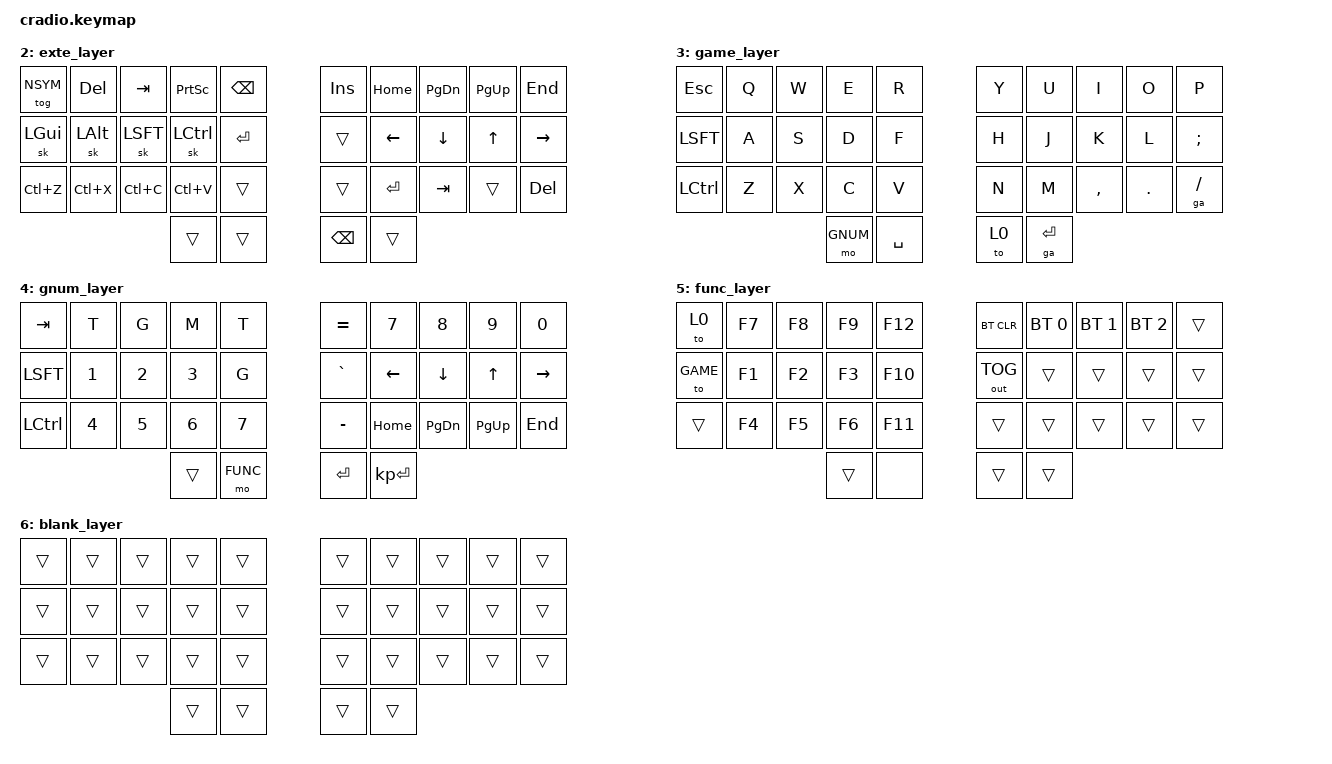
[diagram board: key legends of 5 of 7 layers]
// silicic-zmk cradio (sweep) keymap.
// (c) 2024 `silikeite`.
// SPDX-License-Identifier: MIT

#include <behaviors.dtsi>
#include <dt-bindings/zmk/keys.h>
#include <dt-bindings/zmk/bt.h>
#include <dt-bindings/zmk/outputs.h>

// Layers
#define MAIN 0
#define NSYM 1
#define EXTE 2

#define GAME 3
#define GNUM 4

#define FUNC 5

#define HRML(k1, k2, k3, k4) &ht LGUI k1 &ht LALT k2 &ht LSHFT k3 &ht LCTRL k4
#define HRMR(k1, k2, k3, k4) &ht RCTRL k1 &ht RSHFT k2 &ht RALT k3 &ht RGUI k4

/ {
    behaviors {
        // urob's timeless hold taps
        ht: home_tap {
            compatible = "zmk,behavior-hold-tap";
            #binding-cells = <2>;
            flavor = "balanced";
            tapping-term-ms = <280>;
            quick-tap-ms = <175>;
            require-prior-idle-ms = <150>;
            bindings = <&sk>, <&kp>;
            hold-trigger-on-release;
        };
        tt: thumb_tap {
            compatible = "zmk,behavior-hold-tap";
            #binding-cells = <2>;
            flavor = "hold-preferred";
            tapping-term-ms = <280>;
            quick-tap-ms = <175>;
            require-prior-idle-ms = <150>;
            bindings = <&mo>, <&kp>;
            hold-trigger-on-release;
        };
        ts: thumb_stick {
            compatible = "zmk,behavior-hold-tap";
            #binding-cells = <2>;
            flavor = "balanced";
            tapping-term-ms = <280>;
            quick-tap-ms = <175>;
            require-prior-idle-ms = <150>;
            bindings = <&sl>, <&kpmmCW>;
            hold-trigger-on-release;
        };

        // Mod morph sets.
        kpmmD: mod_morph_d {
            compatible = "zmk,behavior-mod-morph";
            #binding-cells = <0>;
            bindings = <&kp D>, <&kp V>;
            mods = <(MOD_LCTL|MOD_RCTL)>;
            keep-mods = <(MOD_LCTL|MOD_RCTL)>;
        };
        kpmmV: mod_morph_v {
            compatible = "zmk,behavior-mod-morph";
            #binding-cells = <0>;
            bindings = <&kp V>, <&kp D>;
            mods = <(MOD_LCTL|MOD_RCTL)>;
            keep-mods = <(MOD_LCTL|MOD_RCTL)>;
        };
        kpmmCO: mod_morph_comma {
            compatible = "zmk,behavior-mod-morph";
            #binding-cells = <0>;
            bindings = <&kp COMMA>, <&kp LPAR>;
            mods = <(MOD_LSFT|MOD_RSFT)>;
        };
        kpmmDO: mod_morph_dot {
            compatible = "zmk,behavior-mod-morph";
            #binding-cells = <0>;
            bindings = <&kp DOT>, <&kp RPAR>;
            mods = <(MOD_LSFT|MOD_RSFT)>;
        };
        kpmmN1: mod_morph_one {
            compatible = "zmk,behavior-mod-morph";
            #binding-cells = <0>;
            bindings = <&kp N1>, <&kp TILDE>;
            mods = <(MOD_LSFT|MOD_RSFT)>;
        };
        kpmmCW: mod_morph_capsword {
            compatible = "zmk,behavior-mod-morph";
            #binding-cells = <0>;
            bindings = <&sk LSFT>, <&caps_word>;
            mods = <(MOD_LSFT|MOD_RSFT)>;
        };
    };

    combos {
        compatible = "zmk,combos";
        
        // Normal mode cob

        combo_star {
            timeout-ms = <20>;
            layers = <0>;
            key-positions = <6 7>;
            require-prior-idle-ms = <150>;
            bindings = <&kp STAR>;
        };
        combo_minus {
            timeout-ms = <20>;
            layers = <0>;
            key-positions = <16 17>;
            require-prior-idle-ms = <150>;
            bindings = <&kp MINUS>;
        };
        combo_under {
            timeout-ms = <20>;
            layers = <0>;
            key-positions = <17 18>;
            require-prior-idle-ms = <150>;
            bindings = <&kp UNDER>;
        };
        combo_bspc {
            timeout-ms = <20>;
            layers = <0>;
            key-positions = <18 19>;
            require-prior-idle-ms = <150>;
            bindings = <&kp BSPC>;
        };
        combo_colon {
            timeout-ms = <20>;
            layers = <0>;
            key-positions = <26 27>;
            require-prior-idle-ms = <150>;
            bindings = <&kp COLON>;
        };
        combo_semi {
            timeout-ms = <20>;
            layers = <0>;
            key-positions = <27 28>;
            require-prior-idle-ms = <150>;
            bindings = <&kp SEMI>;
        };
        combo_excl {
            timeout-ms = <20>;
            layers = <0>;
            key-positions = <28 29>;
            require-prior-idle-ms = <150>;
            bindings = <&kp EXCL>;
        };

        // Resets
        combo_reset_left {
            timeout-ms = <20>;
            layers = <FUNC>;
            key-positions = <21 22 23>;
            require-prior-idle-ms = <150>;
            bindings = <&bootloader>;
        };
        combo_reset_right {
            timeout-ms = <20>;
            layers = <FUNC>;
            key-positions = <26 27 28>;
            require-prior-idle-ms = <150>;
            bindings = <&bootloader>;
        };

        // Switch to NumLk mode
        combo_mins_left {
            timeout-ms = <20>;
            layers = <NSYM>;
            key-positions = <12 13>;
            require-prior-idle-ms = <150>;
            bindings = <&kp MINUS>;
        };

        combo_esc {
            timeout-ms = <20>;
            layers = <0>;
            key-positions = <30 31>;
            require-prior-idle-ms = <100>;
            bindings = <&kp ESC>;
        };
    };

    macros {
        ga: game_alpha {
            compatible = "zmk,behavior-macro-one-param";
            #binding-cells = <1>;
            bindings
                = <&to 0>
                , <&macro_param_1to1>
                , <&kp MACRO_PLACEHOLDER>
            ;
        };
    };

    keymap {
        compatible = "zmk,keymap";

        // Standard, two-handed layers.

        default_layer {
            bindings = <
        //╭──────────┬──────────┬──────────┬──────────┬──────────╮   ╭──────────┬──────────┬──────────┬──────────┬──────────╮
        //│  Q       │  W       │  F       │  P       │  B       │   │  J       │  L       │  U       │  Y       │  ' "     │
            &kp Q      &kp W      &kp F      &kp P      &kp B          &kp J      &kp L      &kp U      &kp Y      &kp SQT
        //├──────────┼──────────┼──────────┼──────────┼──────────┤   ├──────────┼──────────┼──────────┼──────────┼──────────┤
        //│  A       │  R       │  S       │  T       │  G       │   │  M       │  N      (-) E      (_)  I      │  O       │
            HRML(A,     R,         S,         T)        &kp G          &kp M      HRMR(N,     E,          I,        O)
        //├──────────┼──────────┼──────────┼──────────┼──────────┤   ├──────────┼──────────┼──────────┼──────────┼──────────┤
        //│  Z       │  X       │  C       │  D       │  V       │   │  K       │  H      (:) , (    (;) . )    (!) / ?     │
            &kp Z      &kp X      &kp C      &kpmmD     &kpmmV         &kp K      &kp H      &kpmmCO   &kpmmDO     &kp FSLH
        //╰──────────┴──────────┴──────────┼──────────┼──────────┤   ├──────────┼──────────┼──────────┴──────────┴──────────╯
        //                                 |  Tab/Ex  |  _/Ex    |   | ⬆️/1#    |  ↩️/Fn   |
                                         &tt FUNC TAB &tt EXTE SPACE &ts NSYM 0 &tt FUNC RET
        //                                 ╰──────────┴──────────╯   ╰──────────┴──────────╯
            >;
        };

        nsym_layer {
            bindings = <
        //╭──────────┬──────────┬──────────┬──────────┬──────────╮   ╭──────────┬──────────┬──────────┬──────────┬──────────╮
        //│  ~       │  7 &     │  8 *     │  9 (     │          │   │          │  🌍      │  [       │  ]       │  ` ~     │
            &kp TILDE  &kp N7     &kp N8     &kp N9     &trans         &trans     &kp LANG1  &kp LBKT   &kp RBKT   &kp GRAVE   
        //├──────────┼──────────┼──────────┼──────────┼──────────┤   ├──────────┼──────────┼──────────┼──────────┼──────────┤
        //│  . >     │  1 !     │  2 @     │  3 #     │  = +     │   │          │  📋      │  {       │  }       │  ; :     │
            HRML(DOT,  N1,        N2,        N3)        &kp EQUAL      &trans     HRMR(K_APP, LBRC,     RBRC,      SEMI)  
        //├──────────┼──────────┼──────────┼──────────┼──────────┤   ├──────────┼──────────┼──────────┼──────────┼──────────┤
        //│  , <     │  4 $     │  5 %     │  6 ^     │          │   │          │ = +      │  <       │  >       │  \ |     │
            &kp COMMA  &kp N4     &kp N5     &kp N6     &trans         &trans     &kp EQUAL  &kp LT     &kp GT     &kp BSLH   
        //╰──────────┴──────────┴──────────┼──────────┼──────────┤   ├──────────┼──────────┼──────────┴──────────┴──────────╯
        //                                 |          |  0/Ex    |   | XXXXXXXX |          |
                                             &trans    &tt EXTE N0     &trans     &trans
        //                                 ╰──────────┴──────────╯   ╰──────────┴──────────╯
            >;
        };

        exte_layer {
            bindings = <
        //╭──────────┬──────────┬──────────┬──────────┬──────────╮   ╭──────────┬──────────┬──────────┬──────────┬──────────╮
        //│  NumLk   │  DEL     │  TAB     │  PRINT   │  BSPC    │   │  INS     │  HOME    │  PGDN    │  PGUP    │  END     │
            &tog NSYM  &kp DEL    &kp TAB    &kp PSCRN  &kp BSPC       &kp INS    &kp HOME  &kp PG_DN  &kp PG_UP   &kp END 
        //├──────────┼──────────┼──────────┼──────────┼──────────┤   ├──────────┼──────────┼──────────┼──────────┼──────────┤
        //│  META    │  ALT     │  SHIFT   │  CTRL    │  ↩️      │   │          │  LEFT    │  DOWN    │  UP      │  RIGHT   |
            &sk LGUI   &sk LALT   &sk LSFT   &sk LCTL   &kp RET        &trans     &kp LEFT   &kp DOWN   &kp UP     &kp RIGHT      
        //├──────────┼──────────┼──────────┼──────────┼──────────┤   ├──────────┼──────────┼──────────┼──────────┼──────────┤
        //│  UNDO    │  CUT     │  COPY    │  PASTE   │          │   │          │  RET     │  TAB     │          │   DEL    │
            &kp LC(Z)  &kp LC(X)  &kp LC(C)  &kp LC(V)  &trans         &trans     &kp RET    &kp TAB     &trans     &kp DEL     
        //╰──────────┴──────────┴──────────┼──────────┼──────────┤   ├──────────┼──────────┼──────────┴──────────┴──────────╯
        //                                 |          | XXXXXXXX |   |  BSPC    |          |
                                              &trans    &trans         &kp BSPC  &trans
        //                                 ╰──────────┴──────────╯   ╰──────────┴──────────╯
            >;
        };

        game_layer {
            bindings = <
        //╭──────────┬──────────┬──────────┬──────────┬──────────╮   ╭──────────┬──────────┬──────────┬──────────┬──────────╮
        //│  ESC     │  Q       │  W       │  E       |  R       │   │  Y       │  U       │  I       │  O       │  P       │
            &kp ESC    &kp Q      &kp W      &kp E      &kp R          &kp Y      &kp U      &kp I      &kp O      &kp P
        //├──────────┼──────────┼──────────┼──────────┼──────────┤   ├──────────┼──────────┼──────────┼──────────┼──────────┤
        //│  LSFT    │  A       │  S       │  D       │  F       │   │  H       │  J       │  K       │  L       │  ; :     │
            &kp LSFT   &kp A      &kp S      &kp D      &kp F          &kp H      &kp J      &kp K      &kp L      &kp SEMI
        //├──────────┼──────────┼──────────┼──────────┼──────────┤   ├──────────┼──────────┼──────────┼──────────┼──────────┤
        //│  LCTL    │  Z       │  X       │  C       │  V       │   │  N       │  M       │ , <      │ . >      │ / -> Aa  │
            &kp LCTL   &kp Z      &kp X      &kp C      &kp V          &kp N      &kp M      &kp COMMA  &kp DOT    &ga FSLH
        //╰──────────┴──────────┴──────────┼──────────┼──────────┤   ├──────────┼──────────┼──────────┴──────────┴──────────╯
        //                                 |  1#      |  _       |   |  Aa      | ↩️ -> Aa |
                                             &mo GNUM   &kp SPACE      &to 0      &ga RET
        //                                 ╰──────────┴──────────╯   ╰──────────┴──────────╯
            >;
        };

        gnum_layer {
            bindings = <
        //╭──────────┬──────────┬──────────┬──────────┬──────────╮   ╭──────────┬──────────┬──────────┬──────────┬──────────╮
        //│  TAB     │  T       │  G       │  M       │  Y       │   │  = +     │  7       │  8       │  9       │  0       |
            &kp TAB    &kp T      &kp G      &kp M     &kp T          &kp EQUAL  &kp N7     &kp N8     &kp N9     &kp N0
        //├──────────┼──────────┼──────────┼──────────┼──────────┤   ├──────────┼──────────┼──────────┼──────────┼──────────┤
        //│  LSFT    │  1       │  2       │  3       │  H       │   │  ` ~     │  LEFT    │  DOWN    │  UP      │  RIGHT   │
            &kp LSFT   &kp N1     &kp N2     &kp N3     &kp G          &kp GRAVE  &kp LEFT   &kp DOWN   &kp UP     &kp RIGHT
        //├──────────┼──────────┼──────────┼──────────┼──────────┤   ├──────────┼──────────┼──────────┼──────────┼──────────┤
        //│  LCTL    │  4       │  5       │  6       │  7       │   │  - _     │  HOME    │  PGDN    │  PGUP    │  END     │
            &kp LCTL   &kp N4     &kp N5     &kp N6     &kp N7         &kp MINUS  &kp HOME  &kp PG_DN  &kp PG_UP   &kp END
        //╰──────────┴──────────┴──────────┼──────────┼──────────┤   ├──────────┼──────────┼──────────┴──────────┴──────────╯
        //                                 | XXXXXXXX |  FN      |   |  RET     |  KPRET   |
                                              &trans    &mo FUNC       &kp RET    &kp KP_ENTER
        //                                 ╰──────────┴──────────╯   ╰──────────┴──────────╯
            >;
        };

        func_layer {
            bindings = <
        //╭──────────┬──────────┬──────────┬──────────┬──────────╮   ╭──────────┬──────────┬──────────┬──────────┬──────────╮
        //│  RESET   │  F7      │  F8      │  F9      │  F12     │   │ BT CLR   │ B0       │ B1       │ B2       │          │
            &to 0      &kp F7     &kp F8     &kp F9     &kp F12       &bt BT_CLR  &bt BT_SEL 0 &bt BT_SEL 1 &bt BT_SEL 2 &trans  
        //├──────────┼──────────┼──────────┼──────────┼──────────┤   ├──────────┼──────────┼──────────┼──────────┼──────────┤
        //│          │  F1      │  F2      │  F3      │  F10     │   │ OUT TOG  │          │          │          │          │
            &to GAME   &kp F1     &kp F2     &kp F3     &kp F10      &out OUT_TOG &trans     &trans     &trans     &trans     
        //├──────────┼──────────┼──────────┼──────────┼──────────┤   ├──────────┼──────────┼──────────┼──────────┼──────────┤
        //│          │  F4      │  F5      │  F6      │  F11     │   │          │          │          │          │          │
            &trans     &kp F4     &kp F5     &kp F6     &kp F11        &trans     &trans     &trans     &trans     &trans     
        //╰──────────┴──────────┴──────────┼──────────┼──────────┤   ├──────────┼──────────┼──────────┴──────────┴──────────╯
        //                                 | XXXXXXXX | -------- |   |          |          |
                                              &trans    &none          &trans     &trans
        //                                 ╰──────────┴──────────╯   ╰──────────┴──────────╯
            >;
        };

        blank_layer {
            bindings = <
        //╭──────────┬──────────┬──────────┬──────────┬──────────╮   ╭──────────┬──────────┬──────────┬──────────┬──────────╮
        //│          │          │          │          │          │   │          │          │          │          │          │
            &trans     &trans     &trans     &trans     &trans         &trans     &trans     &trans     &trans     &trans     
        //├──────────┼──────────┼──────────┼──────────┼──────────┤   ├──────────┼──────────┼──────────┼──────────┼──────────┤
        //│          │          │          │          │          │   │          │          │          │          │          │
            &trans     &trans     &trans     &trans     &trans         &trans     &trans     &trans     &trans     &trans     
        //├──────────┼──────────┼──────────┼──────────┼──────────┤   ├──────────┼──────────┼──────────┼──────────┼──────────┤
        //│          │          │          │          │          │   │          │          │          │          │          │
            &trans     &trans     &trans     &trans     &trans         &trans     &trans     &trans     &trans     &trans     
        //╰──────────┴──────────┴──────────┼──────────┼──────────┤   ├──────────┼──────────┼──────────┴──────────┴──────────╯
        //                                 |          |          |   |          |          |
                                              &trans    &trans         &trans     &trans
        //                                 ╰──────────┴──────────╯   ╰──────────┴──────────╯
            >;
        };
    };
};
